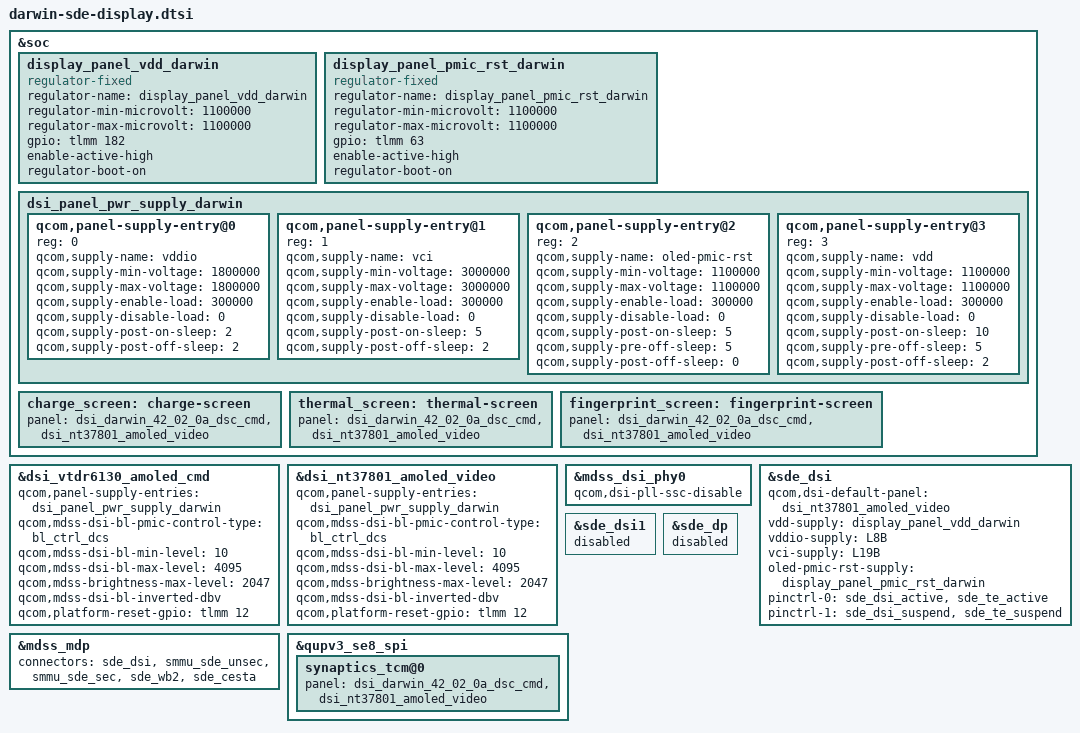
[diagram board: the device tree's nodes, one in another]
#include "../kera-sde-display.dtsi"
#include "../dsi-panel-nt37801-dsc-wqhd-plus-video.dtsi"
#include "dsi-panel-darwin-42-02-0a-dsc-cmd.dtsi"

&soc {
	display_panel_vdd_darwin: display_panel_vdd_darwin {
		compatible = "regulator-fixed";
		regulator-name = "display_panel_vdd_darwin";
		regulator-min-microvolt = <1100000>;
		regulator-max-microvolt = <1100000>;
		gpio = <&tlmm 182 0>;
		enable-active-high;
		regulator-boot-on;
	};

	display_panel_pmic_rst_darwin: display_panel_pmic_rst_darwin {
		compatible = "regulator-fixed";
		regulator-name = "display_panel_pmic_rst_darwin";
		regulator-min-microvolt = <1100000>;
		regulator-max-microvolt = <1100000>;
		gpio = <&tlmm 63 0>;
		enable-active-high;
		regulator-boot-on;
	};

	dsi_panel_pwr_supply_darwin: dsi_panel_pwr_supply_darwin {
		qcom,panel-supply-entry@0 {
			reg = <0>;
			qcom,supply-name = "vddio";
			qcom,supply-min-voltage = <1800000>;
			qcom,supply-max-voltage = <1800000>;
			qcom,supply-enable-load = <300000>;
			qcom,supply-disable-load = <0>;
			qcom,supply-post-on-sleep = <2>;
			qcom,supply-post-off-sleep = <2>;
		};
		qcom,panel-supply-entry@1 {
			reg = <1>;
			qcom,supply-name = "vci";
			qcom,supply-min-voltage = <3000000>;
			qcom,supply-max-voltage = <3000000>;
			qcom,supply-enable-load = <300000>;
			qcom,supply-disable-load = <0>;
			qcom,supply-post-on-sleep = <5>;
			qcom,supply-post-off-sleep = <2>;
		};
		qcom,panel-supply-entry@2 {
			reg = <2>;
			qcom,supply-name = "oled-pmic-rst";
			qcom,supply-min-voltage = <1100000>;
			qcom,supply-max-voltage = <1100000>;
			qcom,supply-enable-load = <300000>;
			qcom,supply-disable-load = <0>;
			qcom,supply-post-on-sleep = <5>;
			qcom,supply-pre-off-sleep = <5>;
			qcom,supply-post-off-sleep = <0>;
		};
		qcom,panel-supply-entry@3 {
			reg = <3>;
			qcom,supply-name = "vdd";
			qcom,supply-min-voltage = <1100000>;
			qcom,supply-max-voltage = <1100000>;
			qcom,supply-enable-load = <300000>;
			qcom,supply-disable-load = <0>;
			qcom,supply-post-on-sleep = <10>;
			qcom,supply-pre-off-sleep = <5>;
			qcom,supply-post-off-sleep = <2>;
		};
	};
};

&dsi_vtdr6130_amoled_cmd {
	qcom,panel-supply-entries = <&dsi_panel_pwr_supply_darwin>;
	qcom,mdss-dsi-bl-pmic-control-type = "bl_ctrl_dcs";
	qcom,mdss-dsi-bl-min-level = <10>;
	qcom,mdss-dsi-bl-max-level = <4095>;
	qcom,mdss-brightness-max-level = <2047>;
	qcom,mdss-dsi-bl-inverted-dbv;
	qcom,platform-reset-gpio = <&tlmm 12 0>;
};

&dsi_nt37801_amoled_video {
	qcom,panel-supply-entries = <&dsi_panel_pwr_supply_darwin>;
	qcom,mdss-dsi-bl-pmic-control-type = "bl_ctrl_dcs";
	qcom,mdss-dsi-bl-min-level = <10>;
	qcom,mdss-dsi-bl-max-level = <4095>;
	qcom,mdss-brightness-max-level = <2047>;
	qcom,mdss-dsi-bl-inverted-dbv;
	qcom,platform-reset-gpio = <&tlmm 12 0>;
};

&mdss_dsi_phy0 {
	qcom,dsi-pll-ssc-disable;
};

&sde_dsi {
	qcom,dsi-default-panel = <&dsi_nt37801_amoled_video>;
	vdd-supply = <&display_panel_vdd_darwin>;
	vddio-supply = <&L8B>;
	vci-supply = <&L19B>;
	oled-pmic-rst-supply = <&display_panel_pmic_rst_darwin>;
	pinctrl-names = "panel_active", "panel_suspend";
	pinctrl-0 = <&sde_dsi_active &sde_te_active>;
	pinctrl-1 = <&sde_dsi_suspend &sde_te_suspend>;
};

&sde_dsi1 {
	status = "disabled";
};

&mdss_mdp {
	connectors = <&sde_dsi &smmu_sde_unsec &smmu_sde_sec &sde_wb2 &sde_cesta>;
};

&sde_dp {
	status = "disabled";
};

&soc {
	charge_screen: charge-screen {
		panel = <&dsi_darwin_42_02_0a_dsc_cmd
		&dsi_nt37801_amoled_video>;
	};
	thermal_screen: thermal-screen {
		panel = <&dsi_darwin_42_02_0a_dsc_cmd
		&dsi_nt37801_amoled_video>;
	};
	fingerprint_screen: fingerprint-screen {
		panel = <&dsi_darwin_42_02_0a_dsc_cmd
		&dsi_nt37801_amoled_video>;
	};
};

&qupv3_se8_spi {
		synaptics_tcm@0 {
			panel  = <&dsi_darwin_42_02_0a_dsc_cmd
				&dsi_nt37801_amoled_video>;
        };
};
